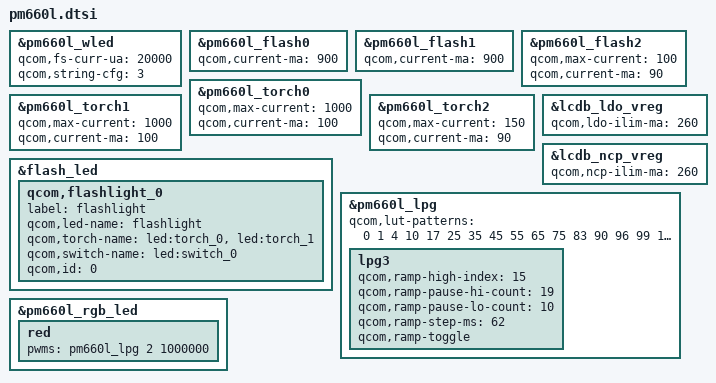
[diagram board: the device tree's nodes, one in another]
&pm660l_wled {
	qcom,fs-curr-ua = <20000>;
	qcom,string-cfg = <3>;
};

&pm660l_flash0 {
	qcom,current-ma = <900>;
};

&pm660l_flash1 {
	qcom,current-ma = <900>;
};

&pm660l_flash2 {
	qcom,max-current = <100>;
	qcom,current-ma = <90>;
};

&pm660l_torch0 {
	qcom,max-current = <1000>;
	qcom,current-ma = <100>;
};

&pm660l_torch1 {
	qcom,max-current = <1000>;
	qcom,current-ma = <100>;
};

&pm660l_torch2 {
	qcom,max-current = <150>;
	qcom,current-ma = <90>;
};

&flash_led {
	qcom,flashlight_0 {
		label = "flashlight";
		qcom,led-name = "flashlight";
		qcom,torch-name = "led:torch_0", "led:torch_1";
		qcom,switch-name = "led:switch_0";
		qcom,id = <0>;
	};
};

&lcdb_ldo_vreg {
	qcom,ldo-ilim-ma = <260>;
};

&lcdb_ncp_vreg {
	qcom,ncp-ilim-ma = <260>;
};

&pm660l_lpg {
	qcom,lut-patterns =	<0 1 4 10 17 25 35 45 55
			65 75 83 90 96 99 100>;

	lpg3 {
		qcom,ramp-high-index = <15>;
		qcom,ramp-pause-hi-count = <19>;
		qcom,ramp-pause-lo-count = <10>;
		qcom,ramp-step-ms = <62>;
		qcom,ramp-toggle;
	};
};

&pm660l_rgb_led {
	red {
		pwms = <&pm660l_lpg 2 1000000>;
	};

	/delete-node/ green;
	/delete-node/ blue;
};
